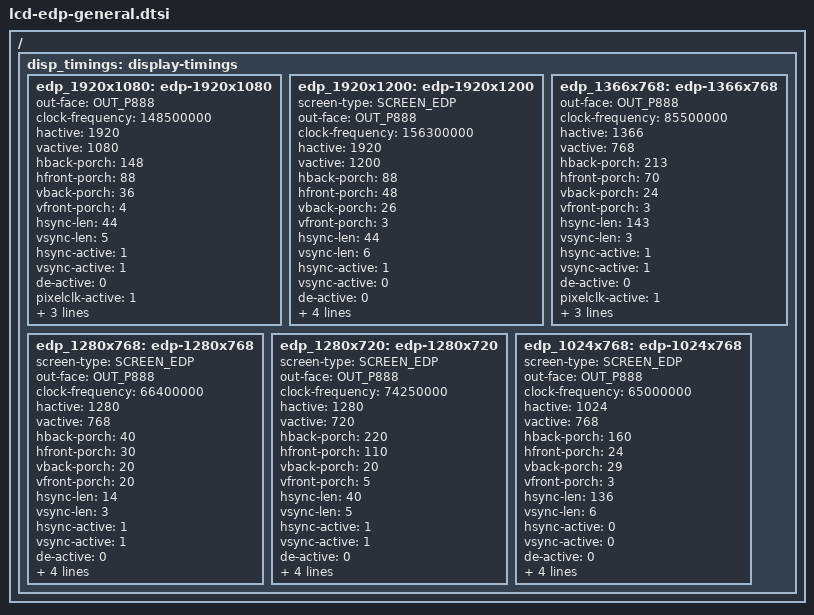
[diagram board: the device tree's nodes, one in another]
/*
 * Advantech. edp general LCD
 *
 */
/ {
	disp_timings: display-timings {
		edp_1920x1080: edp-1920x1080 {
			out-face    = <OUT_P888>;
			clock-frequency = <148500000>;
			hactive = <1920>;
			vactive = <1080>;
			hback-porch = <148>;
			hfront-porch = <88>;
			vback-porch = <36>;
			vfront-porch = <4>;
			hsync-len = <44>;
			vsync-len = <5>;
			hsync-active = <1>;
			vsync-active = <1>;
			de-active = <0>;
			pixelclk-active = <1>;
			swap-rb = <0>;
			swap-rg = <0>;
			swap-gb = <0>;
		};

		edp_1920x1200: edp-1920x1200 {
			screen-type = <SCREEN_EDP>;
			out-face    = <OUT_P888>;
			clock-frequency = <156300000>;
			hactive = <1920>;
			vactive = <1200>;
			hback-porch = <88>;
			hfront-porch = <48>;
			vback-porch = <26>;
			vfront-porch = <3>;
			hsync-len = <44>;
			vsync-len = <6>;
			hsync-active = <1>;
			vsync-active = <0>;
			de-active = <0>;
			pixelclk-active = <1>;
			swap-rb = <0>;
			swap-rg = <0>;
			swap-gb = <0>;
	    };

		edp_1366x768: edp-1366x768 {
			out-face    = <OUT_P888>;
			clock-frequency = <85500000>;
			hactive = <1366>;
			vactive = <768>;
			hback-porch = <213>;
			hfront-porch = <70>;
			vback-porch = <24>;
			vfront-porch = <3>;
			hsync-len = <143>;
			vsync-len = <3>;
			hsync-active = <1>;
			vsync-active = <1>;
			de-active = <0>;
			pixelclk-active = <1>;
			swap-rb = <0>;
			swap-rg = <0>;
			swap-gb = <0>;
		};

		edp_1280x768: edp-1280x768 {
			screen-type = <SCREEN_EDP>;
			out-face    = <OUT_P888>;
			clock-frequency = <66400000>;
			hactive = <1280>;
			vactive = <768>;
			hback-porch = <40>;
			hfront-porch = <30>;
			vback-porch = <20>;
			vfront-porch = <20>;
			hsync-len = <14>;
			vsync-len = <3>;
			hsync-active = <1>;
			vsync-active = <1>;
			de-active = <0>;
			pixelclk-active = <1>;
			swap-rb = <0>;
			swap-rg = <0>;
			swap-gb = <0>;
		};

		edp_1280x720: edp-1280x720 {
			screen-type = <SCREEN_EDP>;
			out-face    = <OUT_P888>;
			clock-frequency = <74250000>;
			hactive = <1280>;
			vactive = <720>;
			hback-porch = <220>;
			hfront-porch = <110>;
			vback-porch = <20>;
			vfront-porch = <5>;
			hsync-len = <40>;
			vsync-len = <5>;
			hsync-active = <1>;
			vsync-active = <1>;
			de-active = <0>;
			pixelclk-active = <1>;
			swap-rb = <0>;
			swap-rg = <0>;
			swap-gb = <0>;
		};

		edp_1024x768: edp-1024x768 {
			screen-type = <SCREEN_EDP>;
			out-face    = <OUT_P888>;
			clock-frequency = <65000000>;
			hactive = <1024>;
			vactive = <768>;
			hback-porch = <160>;
			hfront-porch = <24>;
			vback-porch = <29>;
			vfront-porch = <3>;
			hsync-len = <136>;
			vsync-len = <6>;
			hsync-active = <0>;
			vsync-active = <0>;
			de-active = <0>;
			pixelclk-active = <1>;
			swap-rb = <0>;
			swap-rg = <0>;
			swap-gb = <0>;
		};
	};
};
